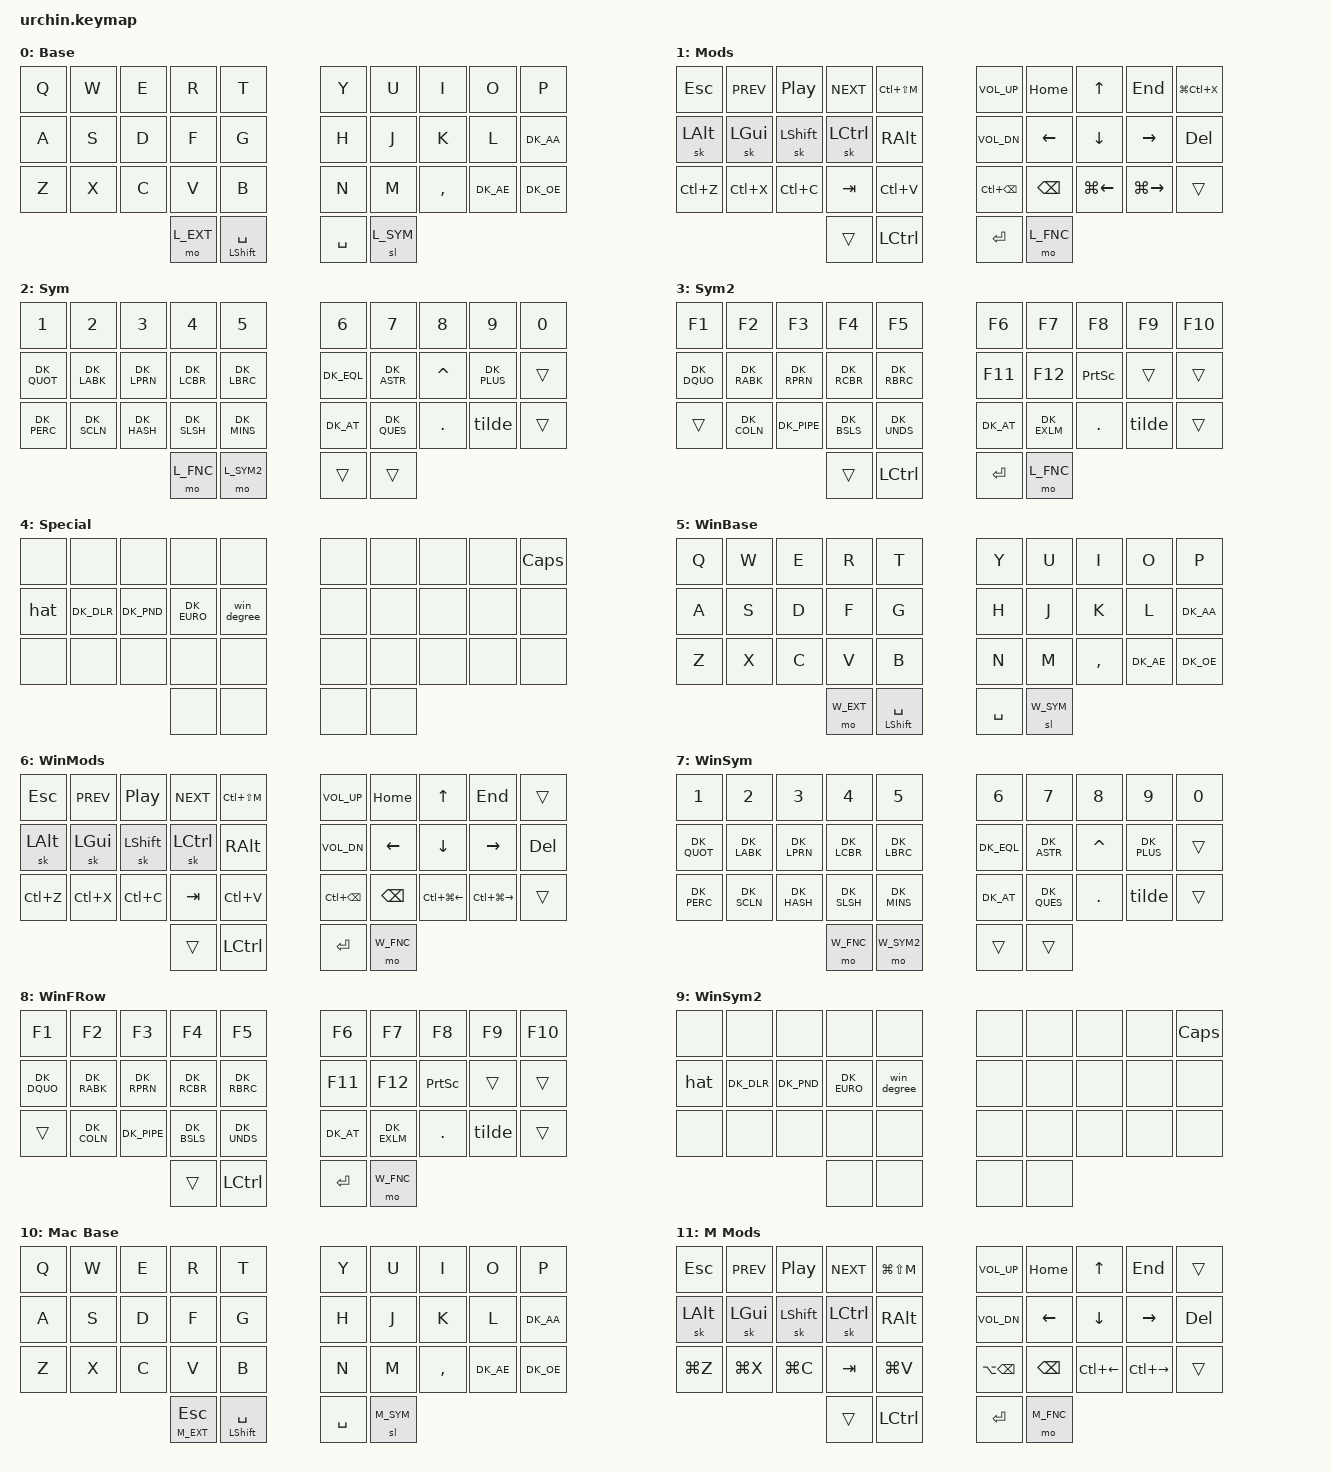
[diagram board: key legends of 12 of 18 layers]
/*
 * Copyright (c) 2020 duckyb
 *
 * SPDX-License-Identifier: MIT
 */

#include <behaviors.dtsi>
#include <dt-bindings/zmk/keys.h>
#include <dt-bindings/zmk/bt.h>
#include <dt-bindings/zmk/outputs.h>
#include "keymap_danish_windows.h"
#include "keymap_danish_mac.h"

// Layer definitions
#define LINUX_BASE 0
#define L_EXT 1
#define L_SYM 2
#define L_FNC 3
#define L_SYM2 4
// -----------------
#define WIN_BASE 5
#define W_EXT 6
#define W_SYM 7
#define W_FNC 8
#define W_SYM2 9
// -----------------
#define MAC_BASE 10
#define M_EXT 11
#define M_SYM 12
#define M_FNC 13
#define M_SYM2 14
// -----------------
#define GAMING 15
#define GAMING_NUMBERS 16
#define SETTINGS 17

&sk {
	// don't release mods on other mods presses
	ignore-modifiers;
};


/ {
	behaviors {
		// Enables holding the first mod-tap key
		// by performing a tap-release-hold sequence.
		// To use it: "&qt KEYCODE1 KEYCODE2"
		qt: quick_tap {
			compatible = "zmk,behavior-hold-tap";
			label = "QUICK_TAP";
			#binding-cells = <2>;
			flavor = "hold-preferred";
			tapping-term-ms = <200>;
			quick-tap-ms = <200>;
			bindings = <&kp>, <&kp>;
		};
	};

	macros {
		// sometimes my device thinks a modifier is being held down
		// pressing all modifiers fixes it.
		unstick: unstick {
			label = "ZM_unstick";
			compatible = "zmk,behavior-macro";
			#binding-cells = <0>;
			bindings = <&kp LSHIFT &kp RSHIFT &kp LCTRL &kp RCTRL &kp LALT &kp RALT &kp LGUI &kp RGUI>;
		};
	tilde: tilde {
            label = "macro_tilde";
            compatible = "zmk,behavior-macro";
            #binding-cells = <0>;
            // Send the dead tilde twice to get a literal "~".
            bindings = <&kp DK_TILD &kp DK_TILD>;
        };
        btick: btick {
            label = "macro_btick";
            compatible = "zmk,behavior-macro";
            #binding-cells = <0>;
            bindings = <&kp DK_ACUT &kp DK_ACUT>;
        };
        hat: hat {
            label = "macro_hat";
            compatible = "zmk,behavior-macro";
            #binding-cells = <0>;
            bindings = <&kp RBRC>;
        };
		win_degree: win_degree {
            label = "macro_win_degree";
            compatible = "zmk,behavior-macro";
            #binding-cells = <0>;
            bindings
			= <&macro_press   &kp LALT>
			, <&macro_tap     &kp KP_N2 &kp KP_N4 &kp KP_N8>
			, <&macro_release &kp LALT>
			;
        };
		mac_degree: mac_degree {
            label = "macro_mac_degree";
            compatible = "zmk,behavior-macro";
            #binding-cells = <0>;
            bindings = <&kp RA(Q)>;
        };
	};

	combos {
		compatible = "zmk,combos";
		// internal-left & external-right thumb keys
		combo_sym2 {
			timeout-ms = <200>;
			key-positions = <31 33>;
			bindings = <&mo L_SYM2>;
		};
		// both left thumb keys
		combo_settings {
			timeout-ms = <200>;
			key-positions = <30 31>;
			bindings = <&mo SETTINGS>;
		};
	};

	keymap {
		compatible = "zmk,keymap";


		//---------------------------------------------------------------------------------------------------------------------------------------------------
		//	Linux layers
		//---------------------------------------------------------------------------------------------------------------------------------------------------


		// Base Linux alpha layer
		default_layer {
            display-name = "Base";
			label = "Base";
			bindings = <
		//╭──────────┬──────────┬──────────┬──────────┬──────────╮   ╭──────────┬──────────┬──────────┬──────────┬──────────╮
            &kp Q      &kp W      &kp E      &kp R      &kp T          &kp Y      &kp U      &kp I      &kp O      &kp P 
        //├──────────┼──────────┼──────────┼──────────┼──────────┤   ├──────────┼──────────┼──────────┼──────────┼──────────┤
            &kp A      &kp S      &kp D      &kp F      &kp G          &kp H      &kp J      &kp K      &kp L      &kp DK_AA
        //├──────────┼──────────┼──────────┼──────────┼──────────┤   ├──────────┼──────────┼──────────┼──────────┼──────────┤
            &kp Z      &kp X      &kp C      &kp V      &kp B          &kp N      &kp M      &kp COMMA  &kp DK_AE  &kp DK_OE
        //╰──────────┴──────────┴──────────┼──────────┼──────────┤   ├──────────┼──────────┼──────────┴──────────┴──────────╯
                                        &mo L_EXT  &qt LSHIFT SPACE   &kp SPACE  &sl L_SYM
        //                                 ╰──────────┴──────────╯   ╰──────────┴──────────╯
			>;
		};

		// Main modifiers and arrow keys
		l_ext_layer {
            display-name = "Mods";
			label = "Mods";
			bindings = <
		//╭──────────┬──────────┬──────────┬──────────┬──────────╮   ╭──────────┬──────────┬──────────┬──────────┬──────────╮
        //│  ESC     │  C_PREV  │  C_PP    │  C_NEXT  │Mute Teams│   │  VOL_UP  │  HOME    │  UP      │  END     │  Voxtype │
            &kp ESC  &kp C_PREV  &kp C_PP  &kp C_NEXT  &kp LC(LS(M)) &kp C_VOL_UP  &kp HOME   &kp UP     &kp END  &kp LG(LC(X))
        //├──────────┼──────────┼──────────┼──────────┼──────────┤   ├──────────┼──────────┼──────────┼──────────┼──────────┤
        //│  LALT    │ L Win    │  LSHIFT  │  LCTRL   │  RALT    │   │  VOL_DN  │  LEFT    │  DOWN    │  RIGHT   │  DEL     │
            &sk LALT  &sk LGUI  &sk LSHIFT  &sk LCTRL  &kp RALT 	  &kp C_VOL_DN   &kp LEFT   &kp DOWN  &kp RIGHT   &kp DEL
        //├──────────┼──────────┼──────────┼──────────┼──────────┤   ├──────────┼──────────┼──────────┼──────────┼──────────┤
        //│   *Z     │   *X     │  *C      │  TAB     │   *V     │   │   *BSPC  │  BSPC    │Desk Left │Desk right│          │
            &kp LC(Z)  &kp LC(X)  &kp LC(C)  &kp TAB    &kp LC(V)    &kp LC(BSPC) &kp BSPC &kp LG(LEFT) &kp LG(RIGHT) &trans
        //╰──────────┴──────────┴──────────┼──────────┼──────────┤   ├──────────┼──────────┼──────────┴──────────┴──────────╯
                                             &trans     &kp LCTRL     &kp ENTER   &mo L_FNC
        //                                 ╰──────────┴──────────╯   ╰──────────┴──────────╯
			>;
		};

		// Numbers and high frequency symbols
		l_sym_layer {
            display-name = "Sym";
			label = "Sym";
			bindings = <
		//╭──────────┬──────────┬──────────┬──────────┬──────────╮   ╭──────────┬──────────┬──────────┬──────────┬──────────╮
        //│  1       │  2       │  3       │  4       │  5       │   │  6       │  7       │  8       │  9       │  0       │
            &kp N1     &kp N2     &kp N3     &kp N4     &kp N5         &kp N6     &kp N7     &kp N8     &kp N9     &kp N0
        //├──────────┼──────────┼──────────┼──────────┼──────────┤   ├──────────┼──────────┼──────────┼──────────┼──────────┤
        //│   '      │  <       │  (       │  {       │  [       │   │  =       │   *      │  &       │   +      │          │
           &kp DK_QUOT &kp DK_LABK &kp DK_LPRN &kp DK_LCBR &kp DK_LBRC   &kp DK_EQL &kp DK_ASTR &kp CARET &kp DK_PLUS  &trans
        //├──────────┼──────────┼──────────┼──────────┼──────────┤   ├──────────┼──────────┼──────────┼──────────┼──────────┤
        //│   %      │   ;      │  #       │  /       │   -      │   │  @       │   ?      │  .       │  ~       │          │
           &kp DK_PERC &kp DK_SCLN &kp DK_HASH &kp DK_SLSH &kp DK_MINS  &kp DK_AT  &kp DK_QUES &kp DOT  &tilde  &trans
        //╰──────────┴──────────┴──────────┼──────────┼──────────┤   ├──────────┼──────────┼──────────┴──────────┴──────────╯
                                            &mo L_FNC  &mo L_SYM2       &trans     &trans
        //                                 ╰──────────┴──────────╯   ╰──────────┴──────────╯
			>;
		};

		// Function keys with modifiers
		l_fnc_layer {
            display-name = "Sym2";
			label = "Sym2";
			bindings = <
		//╭──────────┬──────────┬──────────┬──────────┬──────────╮   ╭──────────┬──────────┬──────────┬──────────┬──────────╮
        //│  F1      │  F2      │  F3      │  F4      │  F5      │   │  F6      │  F7      │  F8      │  F8      │  F10     │
            &kp F1     &kp F2     &kp F3     &kp F4     &kp F5         &kp F6     &kp F7     &kp F8     &kp F9     &kp F10
        //├──────────┼──────────┼──────────┼──────────┼──────────┤   ├──────────┼──────────┼──────────┼──────────┼──────────┤
        //│   "      │  >       │  )       │  }       │  ]       │   │  F11     │  F12     │          │          │          │
          &kp DK_DQUO &kp DK_RABK &kp DK_RPRN &kp DK_RCBR &kp DK_RBRC  &kp F11    &kp F12 &kp PRINTSCREEN  &trans   &trans
        //├──────────┼──────────┼──────────┼──────────┼──────────┤   ├──────────┼──────────┼──────────┼──────────┼──────────┤
        //│          │  :       │  |       │  \       │   _      │   │   @      │  !       │  .       │  ~       │          │
            &trans &kp DK_COLN &kp DK_PIPE &kp DK_BSLS &kp DK_UNDS   &kp DK_AT  &kp DK_EXLM &kp DOT  &tilde  &trans
        //╰──────────┴──────────┴──────────┼──────────┼──────────┤   ├──────────┼──────────┼──────────┴──────────┴──────────╯
                                             &trans     &kp LCTRL      &kp ENTER  &mo L_FNC
        //                                 ╰──────────┴──────────╯   ╰──────────┴──────────╯
			>;
		};

		// Low frequency symbols.
		l_symbols_2_layer {
            display-name = "Special";
			label = "Special";
			bindings = <
		//╭──────────┬──────────┬──────────┬──────────┬──────────╮   ╭──────────┬──────────┬──────────┬──────────┬──────────╮
        //│          │          │          │          │          │   │          │          │          │          │   CAPS   │
            &none 		&none 	   &none 	  &none      &none	        &none      &none 	  &none 	 &none 	   &kp CAPS 
        //├──────────┼──────────┼──────────┼──────────┼──────────┤   ├──────────┼──────────┼──────────┼──────────┼──────────┤
        //│  ^       │   $      │   £      │   €      │   °      │   │          │          │          │          │          │
            &hat 	 &kp DK_DLR  &kp DK_PND   &kp DK_EURO &win_degree	    &none      &none 	  &none 	 &none 		&none 
        //├──────────┼──────────┼──────────┼──────────┼──────────┤   ├──────────┼──────────┼──────────┼──────────┼──────────┤
        //│          │          │          │          │          │   │          │          │          │          │          │
            &none 		&none 	   &none 	  &none      &none	        &none      &none 	  &none 	 &none 		&none 
        //╰──────────┴──────────┴──────────┼──────────┼──────────┤   ├──────────┼──────────┼──────────┴──────────┴──────────╯
                                              &none 	 &none			&none 	   &none 
        //                                 ╰──────────┴──────────╯   ╰──────────┴──────────╯
			>;
		};


		//---------------------------------------------------------------------------------------------------------------------------------------------------
		//	Windows layers
		//---------------------------------------------------------------------------------------------------------------------------------------------------


		// Base windows alpha layer
		win_base_layer {
            display-name = "WinBase";
			label = "WinBase";
			bindings = <
		//╭──────────┬──────────┬──────────┬──────────┬──────────╮   ╭──────────┬──────────┬──────────┬──────────┬──────────╮
            &kp Q      &kp W      &kp E      &kp R      &kp T          &kp Y      &kp U      &kp I      &kp O      &kp P 
        //├──────────┼──────────┼──────────┼──────────┼──────────┤   ├──────────┼──────────┼──────────┼──────────┼──────────┤
            &kp A      &kp S      &kp D      &kp F      &kp G          &kp H      &kp J      &kp K      &kp L      &kp DK_AA
        //├──────────┼──────────┼──────────┼──────────┼──────────┤   ├──────────┼──────────┼──────────┼──────────┼──────────┤
            &kp Z      &kp X      &kp C      &kp V      &kp B          &kp N      &kp M      &kp COMMA  &kp DK_AE  &kp DK_OE
        //╰──────────┴──────────┴──────────┼──────────┼──────────┤   ├──────────┼──────────┼──────────┴──────────┴──────────╯
                                        &mo W_EXT  &qt LSHIFT SPACE   &kp SPACE  &sl W_SYM
        //                                 ╰──────────┴──────────╯   ╰──────────┴──────────╯
			>;
		};

		// Main modifiers and arrow keys
		w_ext_layer {
            display-name = "WinMods";
			label = "WinMods";
			bindings = <
		//╭──────────┬──────────┬──────────┬──────────┬──────────╮   ╭──────────┬──────────┬──────────┬──────────┬──────────╮
        //│  ESC     │  C_PREV  │  C_PP    │  C_NEXT  │Mute Teams│   │  VOL_UP  │  HOME    │  UP      │  END     │          │
            &kp ESC  &kp C_PREV  &kp C_PP  &kp C_NEXT  &kp LC(LS(M)) &kp C_VOL_UP  &kp HOME   &kp UP     &kp END    &trans
        //├──────────┼──────────┼──────────┼──────────┼──────────┤   ├──────────┼──────────┼──────────┼──────────┼──────────┤
        //│  LALT    │ L Win    │  LSHIFT  │  LCTRL   │  RALT    │   │  VOL_DN  │  LEFT    │  DOWN    │  RIGHT   │  DEL     │
            &sk LALT  &sk LGUI  &sk LSHIFT  &sk LCTRL  &kp RALT 	  &kp C_VOL_DN   &kp LEFT   &kp DOWN  &kp RIGHT   &kp DEL
        //├──────────┼──────────┼──────────┼──────────┼──────────┤   ├──────────┼──────────┼──────────┼──────────┼──────────┤
        //│   *Z     │   *X     │  *C      │  TAB     │   *V     │   │   *BSPC  │  BSPC    │Desk Left │Desk right│          │
            &kp LC(Z)  &kp LC(X)  &kp LC(C)  &kp TAB    &kp LC(V)    &kp LC(BSPC) &kp BSPC &kp LC(LG(LEFT)) &kp LC(LG(RIGHT)) &trans
        //╰──────────┴──────────┴──────────┼──────────┼──────────┤   ├──────────┼──────────┼──────────┴──────────┴──────────╯
                                             &trans     &kp LCTRL     &kp ENTER   &mo W_FNC
        //                                 ╰──────────┴──────────╯   ╰──────────┴──────────╯
			>;
		};

		// Numbers and high frequency symbols
		w_sym_layer {
            display-name = "WinSym";
			label = "WinSym";
			bindings = <
		//╭──────────┬──────────┬──────────┬──────────┬──────────╮   ╭──────────┬──────────┬──────────┬──────────┬──────────╮
        //│  1       │  2       │  3       │  4       │  5       │   │  6       │  7       │  8       │  9       │  0       │
            &kp N1     &kp N2     &kp N3     &kp N4     &kp N5         &kp N6     &kp N7     &kp N8     &kp N9     &kp N0
        //├──────────┼──────────┼──────────┼──────────┼──────────┤   ├──────────┼──────────┼──────────┼──────────┼──────────┤
        //│   '      │  <       │  (       │  {       │  [       │   │  =       │   *      │  &       │   +      │          │
           &kp DK_QUOT &kp DK_LABK &kp DK_LPRN &kp DK_LCBR &kp DK_LBRC   &kp DK_EQL &kp DK_ASTR &kp CARET &kp DK_PLUS  &trans
        //├──────────┼──────────┼──────────┼──────────┼──────────┤   ├──────────┼──────────┼──────────┼──────────┼──────────┤
        //│   %      │   ;      │  #       │  /       │   -      │   │  @       │   ?      │  .       │  ~       │          │
           &kp DK_PERC &kp DK_SCLN &kp DK_HASH &kp DK_SLSH &kp DK_MINS  &kp DK_AT  &kp DK_QUES &kp DOT  &tilde  &trans
        //╰──────────┴──────────┴──────────┼──────────┼──────────┤   ├──────────┼──────────┼──────────┴──────────┴──────────╯
                                            &mo W_FNC  &mo W_SYM2       &trans     &trans
        //                                 ╰──────────┴──────────╯   ╰──────────┴──────────╯
			>;
		};

		// Function keys with modifiers
		w_fnc_layer {
            display-name = "WinFRow";
			label = "WinFRow";
			bindings = <
		//╭──────────┬──────────┬──────────┬──────────┬──────────╮   ╭──────────┬──────────┬──────────┬──────────┬──────────╮
        //│  F1      │  F2      │  F3      │  F4      │  F5      │   │  F6      │  F7      │  F8      │  F8      │  F10     │
            &kp F1     &kp F2     &kp F3     &kp F4     &kp F5         &kp F6     &kp F7     &kp F8     &kp F9     &kp F10
        //├──────────┼──────────┼──────────┼──────────┼──────────┤   ├──────────┼──────────┼──────────┼──────────┼──────────┤
        //│   "      │  >       │  )       │  }       │  ]       │   │  F11     │  F12     │          │          │          │
          &kp DK_DQUO &kp DK_RABK &kp DK_RPRN &kp DK_RCBR &kp DK_RBRC  &kp F11    &kp F12 &kp PRINTSCREEN  &trans   &trans
        //├──────────┼──────────┼──────────┼──────────┼──────────┤   ├──────────┼──────────┼──────────┼──────────┼──────────┤
        //│          │  :       │  |       │  \       │   _      │   │   @      │  !       │  .       │  ~       │          │
            &trans &kp DK_COLN &kp DK_PIPE &kp DK_BSLS &kp DK_UNDS   &kp DK_AT  &kp DK_EXLM &kp DOT  &tilde  &trans
        //╰──────────┴──────────┴──────────┼──────────┼──────────┤   ├──────────┼──────────┼──────────┴──────────┴──────────╯
                                             &trans     &kp LCTRL      &kp ENTER  &mo W_FNC
        //                                 ╰──────────┴──────────╯   ╰──────────┴──────────╯
			>;
		};

		// Low frequency symbols.
		w_symbols_2_layer {
            display-name = "WinSym2";
			label = "WinSym2";
			bindings = <
		//╭──────────┬──────────┬──────────┬──────────┬──────────╮   ╭──────────┬──────────┬──────────┬──────────┬──────────╮
        //│          │          │          │          │          │   │          │          │          │          │   CAPS   │
            &none 		&none 	   &none 	  &none      &none	        &none      &none 	  &none 	 &none 	   &kp CAPS 
        //├──────────┼──────────┼──────────┼──────────┼──────────┤   ├──────────┼──────────┼──────────┼──────────┼──────────┤
        //│  ^       │   $      │   £      │   €      │   °      │   │          │          │          │          │          │
            &hat 	 &kp DK_DLR  &kp DK_PND   &kp DK_EURO &win_degree	    &none      &none 	  &none 	 &none 		&none
        //├──────────┼──────────┼──────────┼──────────┼──────────┤   ├──────────┼──────────┼──────────┼──────────┼──────────┤
        //│          │          │          │          │          │   │          │          │          │          │          │
            &none 		&none 	   &none 	  &none      &none	        &none      &none 	  &none 	 &none 		&none 
        //╰──────────┴──────────┴──────────┼──────────┼──────────┤   ├──────────┼──────────┼──────────┴──────────┴──────────╯
                                              &none 	 &none			&none 	   &none 
        //                                 ╰──────────┴──────────╯   ╰──────────┴──────────╯
			>;
		};


		//---------------------------------------------------------------------------------------------------------------------------------------------------
		//	Mac Layers
		//---------------------------------------------------------------------------------------------------------------------------------------------------


		// Base mac aplha layer
		mac_base_layer {
            display-name = "Mac Base";
			label = "Mac Base";
			bindings = <
		//╭──────────┬──────────┬──────────┬──────────┬──────────╮   ╭──────────┬──────────┬──────────┬──────────┬──────────╮
            &kp Q      &kp W      &kp E      &kp R      &kp T          &kp Y      &kp U      &kp I      &kp O      &kp P 
        //├──────────┼──────────┼──────────┼──────────┼──────────┤   ├──────────┼──────────┼──────────┼──────────┼──────────┤
            &kp A      &kp S      &kp D      &kp F      &kp G          &kp H      &kp J      &kp K      &kp L      &kp DK_AA
        //├──────────┼──────────┼──────────┼──────────┼──────────┤   ├──────────┼──────────┼──────────┼──────────┼──────────┤
            &kp Z      &kp X      &kp C      &kp V      &kp B          &kp N      &kp M      &kp COMMA  &kp DK_AE  &kp DK_OE
        //╰──────────┴──────────┴──────────┼──────────┼──────────┤   ├──────────┼──────────┼──────────┴──────────┴──────────╯
                                        &lt M_EXT ESC  &qt LSHIFT SPACE   &kp SPACE  &sl M_SYM
        //                                 ╰──────────┴──────────╯   ╰──────────┴──────────╯
			>;
		};

		// Main modifiers and arrow keys
		m_ext_layer {
            display-name = "M Mods";
			label = "M Mods";
			bindings = <
		//╭──────────┬──────────┬──────────┬──────────┬──────────╮   ╭──────────┬──────────┬──────────┬──────────┬──────────╮
        //│  ESC     │  C_PREV  │  C_PP    │  C_NEXT  │Mute Teams│   │  VOL_UP  │  HOME    │  UP      │  END     │          │
            &kp ESC  &kp C_PREV  &kp C_PP  &kp C_NEXT  &kp LG(LS(M)) &kp C_VOL_UP  &kp HOME   &kp UP     &kp END    &trans
        //├──────────┼──────────┼──────────┼──────────┼──────────┤   ├──────────┼──────────┼──────────┼──────────┼──────────┤
        //│  LALT    │ L Win    │  LSHIFT  │  LCTRL   │  RALT    │   │  VOL_DN  │  LEFT    │  DOWN    │  RIGHT   │  DEL     │
            &sk LALT  &sk LGUI  &sk LSHIFT  &sk LCTRL  &kp RALT 	  &kp C_VOL_DN   &kp LEFT   &kp DOWN  &kp RIGHT   &kp DEL
        //├──────────┼──────────┼──────────┼──────────┼──────────┤   ├──────────┼──────────┼──────────┼──────────┼──────────┤
        //│   *Z     │   *X     │  *C      │  TAB     │   *V     │   │   *BSPC  │  BSPC    │Desk Left │Desk right│          │
            &kp LG(Z) &kp LG(X)  &kp LG(C)   &kp TAB   &kp LG(V)     &kp LA(BSPC) &kp BSPC &kp LC(LEFT) &kp LC(RIGHT) &trans
        //╰──────────┴──────────┴──────────┼──────────┼──────────┤   ├──────────┼──────────┼──────────┴──────────┴──────────╯
                                             &trans     &kp LCTRL     &kp ENTER   &mo M_FNC
        //                                 ╰──────────┴──────────╯   ╰──────────┴──────────╯
			>;
		};

		// Numbers and high frequency symbols
		m_sym_layer {
            display-name = "M Sym";
			label = "M Sym";
			bindings = <
		//╭──────────┬──────────┬──────────┬──────────┬──────────╮   ╭──────────┬──────────┬──────────┬──────────┬──────────╮
        //│  1       │  2       │  3       │  4       │  5       │   │  6       │  7       │  8       │  9       │  0       │
            &kp N1     &kp N2     &kp N3     &kp N4     &kp N5         &kp N6     &kp N7     &kp N8     &kp N9     &kp N0
        //├──────────┼──────────┼──────────┼──────────┼──────────┤   ├──────────┼──────────┼──────────┼──────────┼──────────┤
        //│  '       │  <       │  (       │  {       │  [       │   │  =       │  *       │  &       │          │          │
           &kp DK_QUOT  &kp DK_LABK &kp DK_LPRN &kp DK_MAC_LCBR &kp DK_LBRC &kp DK_EQL &kp DK_ASTR &kp CARET &kp DK_PLUS    &trans
        //├──────────┼──────────┼──────────┼──────────┼──────────┤   ├──────────┼──────────┼──────────┼──────────┼──────────┤
        //│  %       │   ;      │  #       │  /       │   -      │   │  @       │  ?       │  .       │  ~       │          │
           &kp DK_PERC &kp DK_SCLN &kp DK_HASH &kp DK_SLSH &kp DK_MINS  &kp DK_MAC_AT  &kp DK_QUES &kp DOT  &tilde  &trans
        //╰──────────┴──────────┴──────────┼──────────┼──────────┤   ├──────────┼──────────┼──────────┴──────────┴──────────╯
                                            &mo M_FNC  &mo M_SYM2       &trans     &trans
        //                                 ╰──────────┴──────────╯   ╰──────────┴──────────╯
			>;
		};

		// Function keys with modifiers
		m_fnc_layer {
            display-name = "M FRow";
			label = "M FRow";
			bindings = <
		//╭──────────┬──────────┬──────────┬──────────┬──────────╮   ╭──────────┬──────────┬──────────┬──────────┬──────────╮
        //│  F1      │  F2      │  F3      │  F4      │  F5      │   │  F6      │  F7      │  F8      │  F8      │  F10     │
            &kp F1     &kp F2     &kp F3     &kp F4     &kp F5         &kp F6     &kp F7     &kp F8     &kp F9     &kp F10
        //├──────────┼──────────┼──────────┼──────────┼──────────┤   ├──────────┼──────────┼──────────┼──────────┼──────────┤
        //│   "      │  >       │  )       │  }       │  ]       │   │  F11     │  F12     │          │          │          │
        &kp DK_DQUO &kp DK_RABK &kp DK_RPRN &kp DK_MAC_RCBR &kp DK_RBRC  &kp F11  &kp F12 &kp PRINTSCREEN  &trans   &trans
        //├──────────┼──────────┼──────────┼──────────┼──────────┤   ├──────────┼──────────┼──────────┼──────────┼──────────┤
        //│          │  :       │  |       │  \       │   _      │   │   @      │  !       │  .       │  ~       │          │
         &trans &kp DK_COLN &kp DK_MAC_PIPE &kp DK_MAC_BSLS &kp DK_UNDS &kp DK_MAC_AT &kp DK_EXLM &kp DOT  &tilde  &trans
        //╰──────────┴──────────┴──────────┼──────────┼──────────┤   ├──────────┼──────────┼──────────┴──────────┴──────────╯
                                             &trans     &kp LCTRL      &kp ENTER  &mo M_FNC
        //                                 ╰──────────┴──────────╯   ╰──────────┴──────────╯
			>;
		};

		// Low frequency symbols.
		m_symbols_2_layer {
            display-name = "M Sym2";
			label = "M Sym2";
			bindings = <
		//╭──────────┬──────────┬──────────┬──────────┬──────────╮   ╭──────────┬──────────┬──────────┬──────────┬──────────╮
        //│          │          │          │          │          │   │          │          │          │          │   CAPS   │
            &none 		&none 	   &none 	  &none      &none	        &none      &none 	  &none 	 &none 	   &kp CAPS 
        //├──────────┼──────────┼──────────┼──────────┼──────────┤   ├──────────┼──────────┼──────────┼──────────┼──────────┤
        //│  ^       │   $      │   £      │   €      │   °      │   │          │          │          │          │          │
            &none &kp DK_MAC_DLR &kp DK_MAC_PND &kp DK_MAC_EURO &mac_degree	&none      &none 	  &none 	 &none 		&none
        //├──────────┼──────────┼──────────┼──────────┼──────────┤   ├──────────┼──────────┼──────────┼──────────┼──────────┤
        //│          │          │          │          │          │   │          │          │          │          │          │
            &none 		&none 	   &none 	  &none      &none	        &none      &none 	  &none 	 &none 		&none 
        //╰──────────┴──────────┴──────────┼──────────┼──────────┤   ├──────────┼──────────┼──────────┴──────────┴──────────╯
                                              &none 	 &none			&none 	   &none 
        //                                 ╰──────────┴──────────╯   ╰──────────┴──────────╯
			>;
		};
		//---------------------------------------------------------------------------------------------------------------------------------------------------
		//	Gaming layers
		//---------------------------------------------------------------------------------------------------------------------------------------------------


        // Used in games with better positioning of asdw.
		gaming_layer {
            display-name = "Gaming";
			label = "gaming";
			bindings = <

		//╭──────────┬──────────┬──────────┬──────────┬──────────╮   ╭──────────┬──────────┬──────────┬──────────┬──────────╮
            &kp ESC     &kp Q      &kp W      &kp E      &kp R          &kp T      &kp Y      &kp U      &kp I      &kp O
        //├──────────┼──────────┼──────────┼──────────┼──────────┤   ├──────────┼──────────┼──────────┼──────────┼──────────┤
            &kp TAB     &kp A      &kp S      &kp D      &kp F          &kp G      &kp H      &kp J      &kp K      &kp L
        //├──────────┼──────────┼──────────┼──────────┼──────────┤   ├──────────┼──────────┼──────────┼──────────┼──────────┤
            &kp LALT    &kp Z      &kp X      &kp C      &kp V          &kp B      &kp N      &kp M      &kp COMMA  &kp DK_AE
        //╰──────────┴──────────┴──────────┼──────────┼──────────┤   ├──────────┼──────────┼──────────┴──────────┴──────────╯
                                            &kp LSHIFT	&kp LCTRL      &kp SPACE &mo GAMING_NUMBERS 
        //                                 ╰──────────┴──────────╯   ╰──────────┴──────────╯
				>;
		};

        // Used in games to access numbers
		gaming_numbers_layer {
            display-name = "Gaming#";
			label = "gaming#";
			bindings = <

		//╭──────────┬──────────┬──────────┬──────────┬──────────╮   ╭──────────┬──────────┬──────────┬──────────┬──────────╮
              &none     &kp N1     &kp N2     &kp N3     &none          &none      &none      &none      &none      &none
        //├──────────┼──────────┼──────────┼──────────┼──────────┤   ├──────────┼──────────┼──────────┼──────────┼──────────┤
              &none     &kp N4     &kp N5     &kp N6     &none          &none      &none      &none      &none      &none
        //├──────────┼──────────┼──────────┼──────────┼──────────┤   ├──────────┼──────────┼──────────┼──────────┼──────────┤
              &none     &kp N7     &kp N8     &kp N9     &none          &none      &none      &none      &none      &none
        //╰──────────┴──────────┴──────────┼──────────┼──────────┤   ├──────────┼──────────┼──────────┴──────────┴──────────╯
                                              &kp N0 	 &none          &none      &none 
        //                                 ╰──────────┴──────────╯   ╰──────────┴──────────╯
				>;
		};


        //---------------------------------------------------------------------------------------------------------------------------------------------------
		//	Common layers
		//---------------------------------------------------------------------------------------------------------------------------------------------------

		// Used to change the keyboard's settings.
		settings_layer {
            display-name = "Settings";
			label = "Settings";
			bindings = <

		//╭──────────┬──────────┬──────────┬──────────┬──────────╮   ╭──────────┬──────────┬──────────┬──────────┬──────────╮
        //│bootloader│          │          │ BT_CLR   │ BT_SEL 0 │   │ BT_SEL 3 │          │ Unstick  │          │bootloader│          
           &bootloader  &none      &none   &bt BT_CLR &bt BT_SEL 0   &bt BT_SEL 3  &none     &unstick    &none    &bootloader
        //├──────────┼──────────┼──────────┼──────────┼──────────┤   ├──────────┼──────────┼──────────┼──────────┼──────────┤
        //│          │          │          │          │ BT_SEL 1 │   │ BT_SEL 4 │          │          │          │ Soft Off │
            &none 		&none 	   &none 	  &none   &bt BT_SEL 1	 &bt BT_SEL 4  &none 	  &none 	 &none 		&soft_off 
        //├──────────┼──────────┼──────────┼──────────┼──────────┤   ├──────────┼──────────┼──────────┼──────────┼──────────┤
        //│          │          │          │          │ BT_SEL 2 │   │ BT_SEL 5 │          │          │          │          │
             &none 		&none 	   &none 	  &none   &bt BT_SEL 2	 &bt BT_SEL 5  &none 	  &none   &to MAC_BASE &to GAMING
        //╰──────────┴──────────┴──────────┼──────────┼──────────┤   ├──────────┼──────────┼──────────┴──────────┴──────────╯
                                              &none 	 &none		 &to WIN_BASE &to LINUX_BASE 
        //                                 ╰──────────┴──────────╯   ╰──────────┴──────────╯
				>;
		};

	};
};
